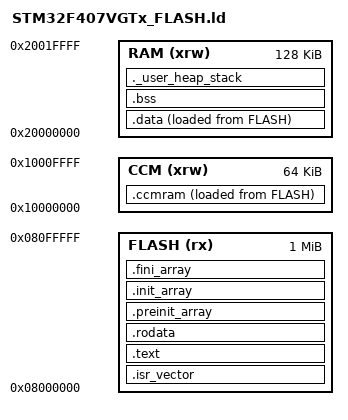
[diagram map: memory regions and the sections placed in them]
/* STM32F407VG: 1 MB flash, 128 KB SRAM (SRAM1 + SRAM2), 64 KB CCM RAM.
   Compatible with the symbols of a CubeMX linker script, so CubeMX code (sysmem.c, startup)
   links as well. */
ENTRY(Reset_Handler)

MEMORY
{
  FLASH (rx) : ORIGIN = 0x08000000, LENGTH = 1024K
  RAM (xrw)  : ORIGIN = 0x20000000, LENGTH = 128K
  CCM (xrw)  : ORIGIN = 0x10000000, LENGTH = 64K
}

_estack = ORIGIN(RAM) + LENGTH(RAM);
/* Space the link must leave free for the heap and the stack (checked at link time). */
_Min_Heap_Size = 0x200;
_Min_Stack_Size = 0x400;

SECTIONS
{
  .isr_vector : { . = ALIGN(4); KEEP(*(.isr_vector)) . = ALIGN(4); } > FLASH

  .text : {
    . = ALIGN(4);
    *(.text)
    *(.text*)
    *(.glue_7)
    *(.glue_7t)
    *(.eh_frame)
    KEEP(*(.init))
    KEEP(*(.fini))
    . = ALIGN(4);
    _etext = .;
  } > FLASH

  .rodata : { . = ALIGN(4); *(.rodata) *(.rodata*) . = ALIGN(4); } > FLASH

  /* Static constructors (C++, __attribute__((constructor))), run by __libc_init_array. */
  .preinit_array : {
    PROVIDE_HIDDEN(__preinit_array_start = .);
    KEEP(*(.preinit_array*))
    PROVIDE_HIDDEN(__preinit_array_end = .);
  } > FLASH
  .init_array : {
    PROVIDE_HIDDEN(__init_array_start = .);
    KEEP(*(SORT(.init_array.*)))
    KEEP(*(.init_array*))
    PROVIDE_HIDDEN(__init_array_end = .);
  } > FLASH
  .fini_array : {
    PROVIDE_HIDDEN(__fini_array_start = .);
    KEEP(*(SORT(.fini_array.*)))
    KEEP(*(.fini_array*))
    PROVIDE_HIDDEN(__fini_array_end = .);
  } > FLASH

  /* Initialized data: stored in flash, copied to RAM by Reset_Handler (word by word, so the
     bounds are 4-aligned). */
  _sidata = LOADADDR(.data);
  .data : {
    . = ALIGN(4);
    _sdata = .;
    *(.data)
    *(.data*)
    *(.RamFunc)
    *(.RamFunc*)
    . = ALIGN(4);
    _edata = .;
  } > RAM AT > FLASH

  /* Variables placed in CCM RAM with __attribute__((section(".ccmram"))). */
  _siccmram = LOADADDR(.ccmram);
  .ccmram : {
    . = ALIGN(4);
    _sccmram = .;
    *(.ccmram)
    *(.ccmram*)
    . = ALIGN(4);
    _eccmram = .;
  } > CCM AT > FLASH

  .bss : {
    . = ALIGN(4);
    _sbss = .;
    __bss_start__ = _sbss;
    *(.bss)
    *(.bss*)
    *(COMMON)
    . = ALIGN(4);
    _ebss = .;
    __bss_end__ = _ebss;
  } > RAM

  /* Heap start for newlib's _sbrk (malloc, and printf/snprintf in newlib-nano): the heap grows
     from the end of .bss towards the stack. Without `end` any firmware using them fails to link
     with "undefined reference to `end'". */
  ._user_heap_stack : {
    . = ALIGN(8);
    PROVIDE(end = .);
    PROVIDE(_end = .);
    . = . + _Min_Heap_Size;
    . = . + _Min_Stack_Size;
    . = ALIGN(8);
  } > RAM

  /DISCARD/ : { *(.ARM.exidx*) *(.ARM.extab*) *(.note.GNU-stack) }
  .ARM.attributes 0 : { *(.ARM.attributes) }
  PROVIDE(__exidx_start = 0);
  PROVIDE(__exidx_end = 0);
}
